VERSION ""

NS_ :

BS_:

BU_:

BO_ 3 RESPONSE_ID: 2 Vector__XXX
 SG_ ID : 0|11@1- (1,0) [0|0] "" Vector__XXX

BO_ 2 REQUEST_ID: 2 Vector__XXX
 SG_ ID : 0|11@1- (1,0) [0|0] "" Vector__XXX

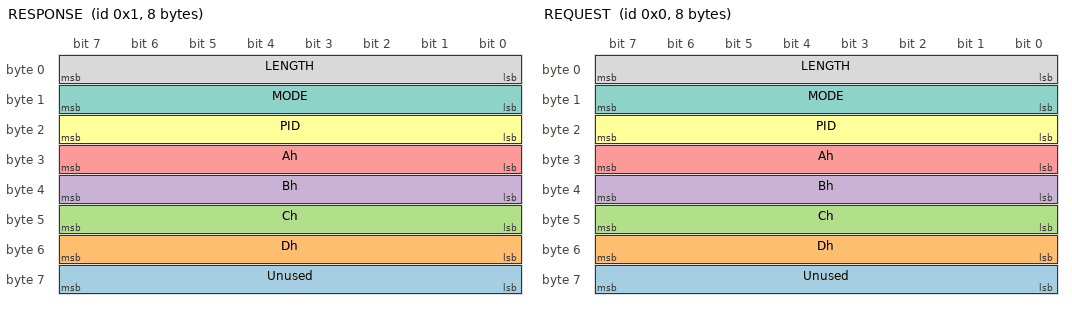
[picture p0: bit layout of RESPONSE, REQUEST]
BO_ 1 RESPONSE: 8 Vector__XXX
 SG_ Unused : 56|8@1- (1,0) [0|0] "" Vector__XXX
 SG_ Dh : 48|8@1- (1,0) [0|0] "" Vector__XXX
 SG_ Ch : 40|8@1- (1,0) [0|0] "" Vector__XXX
 SG_ Bh : 32|8@1- (1,0) [0|0] "" Vector__XXX
 SG_ Ah : 24|8@1- (1,0) [0|0] "" Vector__XXX
 SG_ PID : 16|8@1- (1,0) [0|0] "" Vector__XXX
 SG_ MODE : 8|8@1- (1,0) [0|0] "" Vector__XXX
 SG_ LENGTH : 0|8@1- (1,0) [0|0] "" Vector__XXX

BO_ 0 REQUEST: 8 Vector__XXX
 SG_ Unused : 56|8@1- (1,0) [0|0] "" Vector__XXX
 SG_ Dh : 48|8@1- (1,0) [0|0] "" Vector__XXX
 SG_ Ch : 40|8@1- (1,0) [0|0] "" Vector__XXX
 SG_ Bh : 32|8@1- (1,0) [0|0] "" Vector__XXX
 SG_ Ah : 24|8@1- (1,0) [0|0] "" Vector__XXX
 SG_ PID : 16|8@1- (1,0) [0|0] "" Vector__XXX
 SG_ MODE : 8|8@1- (1,0) [0|0] "" Vector__XXX
 SG_ LENGTH : 0|8@1- (1,0) [0|0] "" Vector__XXX
